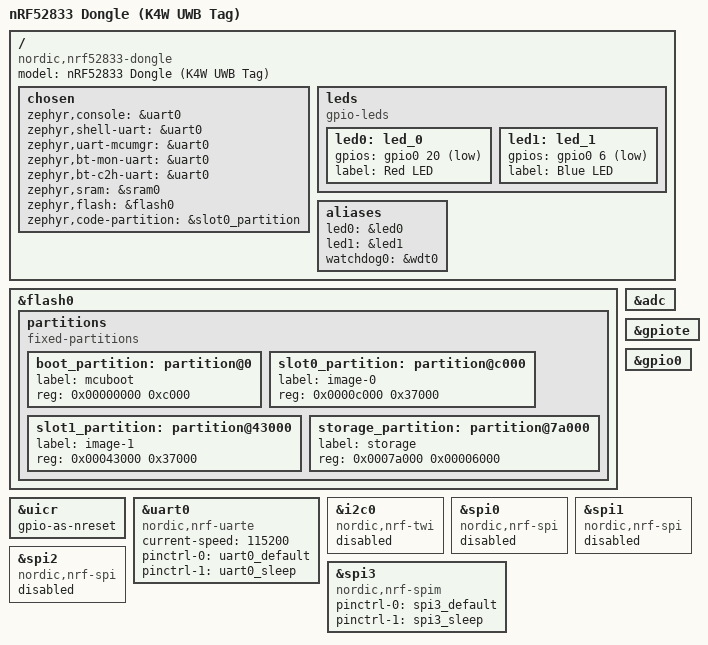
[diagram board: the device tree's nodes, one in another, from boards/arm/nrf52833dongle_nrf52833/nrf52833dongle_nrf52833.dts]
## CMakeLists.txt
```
cmake_minimum_required(VERSION 3.20.0)

# Set board root directory
set(BOARD_ROOT ${CMAKE_CURRENT_SOURCE_DIR})

find_package(Zephyr REQUIRED HINTS $ENV{ZEPHYR_BASE})
project(UWB_TAG_FIRMWARE)

target_sources(app PRIVATE 
    src/main.c
    src/uwb_driver.c
)
```

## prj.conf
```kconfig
# UWB TAG FIRMWARE - Minimal TX Configuration
CONFIG_SERIAL=y
CONFIG_GPIO=y
CONFIG_SPI=y

# Logging Configuration
CONFIG_LOG=y
CONFIG_LOG_DEFAULT_LEVEL=4
CONFIG_LOG_MODE_IMMEDIATE=y
CONFIG_USE_SEGGER_RTT=y
CONFIG_LOG_BACKEND_RTT=y
CONFIG_RTT_CONSOLE=y
```

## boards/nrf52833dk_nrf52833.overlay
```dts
/ {
	chosen {
		zephyr,code-partition = &code_partition;
	};
};

&flash0 {
	partitions {
		compatible = "fixed-partitions";
		#address-cells = <1>;
		#size-cells = <1>;

		code_partition: partition@0 {
			label = "code";
			reg = <0x0 DT_SIZE_K(512)>;
		};
	};
};
```

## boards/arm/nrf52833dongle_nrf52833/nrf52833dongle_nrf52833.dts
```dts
/*
 * Copyright (c) 2024 K4W UWB Tag
 * SPDX-License-Identifier: Apache-2.0
 */

/dts-v1/;
#include <nordic/nrf52833_qdaa.dtsi>
#include "nrf52833dongle_nrf52833-pinctrl.dtsi"

/ {
	model = "nRF52833 Dongle (K4W UWB Tag)";
	compatible = "nordic,nrf52833-dongle";

	chosen {
		zephyr,console = &uart0;
		zephyr,shell-uart = &uart0;
		zephyr,uart-mcumgr = &uart0;
		zephyr,bt-mon-uart = &uart0;
		zephyr,bt-c2h-uart = &uart0;
		zephyr,sram = &sram0;
		zephyr,flash = &flash0;
		zephyr,code-partition = &slot0_partition;
	};

	leds {
		compatible = "gpio-leds";
		led0: led_0 {
			gpios = <&gpio0 20 GPIO_ACTIVE_LOW>;
			label = "Red LED";
		};
		led1: led_1 {
			gpios = <&gpio0 6 GPIO_ACTIVE_LOW>;
			label = "Blue LED";
		};
	};

	aliases {
		led0 = &led0;
		led1 = &led1;
		watchdog0 = &wdt0;
	};
};

&flash0 {
	partitions {
		compatible = "fixed-partitions";
		#address-cells = <1>;
		#size-cells = <1>;

		boot_partition: partition@0 {
			label = "mcuboot";
			reg = <0x00000000 0xc000>;
		};
		slot0_partition: partition@c000 {
			label = "image-0";
			reg = <0x0000c000 0x37000>;
		};
		slot1_partition: partition@43000 {
			label = "image-1";
			reg = <0x00043000 0x37000>;
		};
		storage_partition: partition@7a000 {
			label = "storage";
			reg = <0x0007a000 0x00006000>;
		};
	};
};

&adc {
	status = "okay";
};

&uicr {
	gpio-as-nreset;
};

&gpiote {
	status = "okay";
};

&gpio0 {
	status = "okay";
};

&uart0 {
	compatible = "nordic,nrf-uarte";
	status = "okay";
	current-speed = <115200>;
	pinctrl-0 = <&uart0_default>;
	pinctrl-1 = <&uart0_sleep>;
	pinctrl-names = "default", "sleep";
};

&i2c0 {
	compatible = "nordic,nrf-twi";
	status = "disabled";
};

&spi0 {
	compatible = "nordic,nrf-spi";
	status = "disabled";
};

&spi1 {
	compatible = "nordic,nrf-spi";
	status = "disabled";
};

&spi2 {
	compatible = "nordic,nrf-spi";
	status = "disabled";
};

&spi3 {
	compatible = "nordic,nrf-spim";
	status = "okay";
	pinctrl-0 = <&spi3_default>;
	pinctrl-1 = <&spi3_sleep>;
	pinctrl-names = "default", "sleep";
};
```

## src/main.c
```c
#include <zephyr/kernel.h>
#include <zephyr/logging/log.h>

LOG_MODULE_REGISTER(uwb_tag_firmware, CONFIG_LOG_DEFAULT_LEVEL);

/* Forward declaration of UWB driver functions */
extern int uwb_driver_init(void);
extern int uwb_send_blink(void);

/**
 * Main application entry point
 * UWB TAG FIRMWARE - TX Mode (Transmitter/BLINK)
 * 
 * This firmware runs the NRF52833 in TX-only mode:
 * - Sends UWB BLINK frames every 500ms
 * - Enters sleep mode for 490ms between transmissions
 * - NO RX (receive) functionality
 */
int main(void)
{
    int ret = 0;

    LOG_INF("===========================================");
    LOG_INF("UWB TAG FIRMWARE - TX MODE (TRANSMITTER)");
    LOG_INF("===========================================");
    LOG_INF("Platform: NRF52833");
    LOG_INF("Transceiver: Qorvo DW3210");
    LOG_INF("RTOS: Zephyr");
    LOG_INF("===========================================");

    /* Initialize UWB driver and DW3210 transceiver */
    ret = uwb_driver_init();
    if (ret) {
        LOG_ERR("Failed to initialize UWB driver: %d", ret);
        return ret;
    }

    LOG_INF("UWB Driver initialized successfully");
    LOG_INF("Entering TX transmission loop...");
    LOG_INF("Transmission interval: 500ms");
    k_msleep(500);

    /* Main TX loop - Send BLINK frame every 500ms */
    while (1) {
        /* Send UWB BLINK frame (TX operation) */
        ret = uwb_send_blink();
        if (ret) {
            LOG_ERR("Failed to send BLINK frame: %d", ret);
        }

        /* Sleep for 490ms to achieve 500ms transmission interval */
        /* (100ms transmission time + 490ms sleep = 500ms cycle) */
        LOG_DBG("Entering sleep mode for 490ms...");
        k_msleep(490);
    }

    return 0;
}
```
